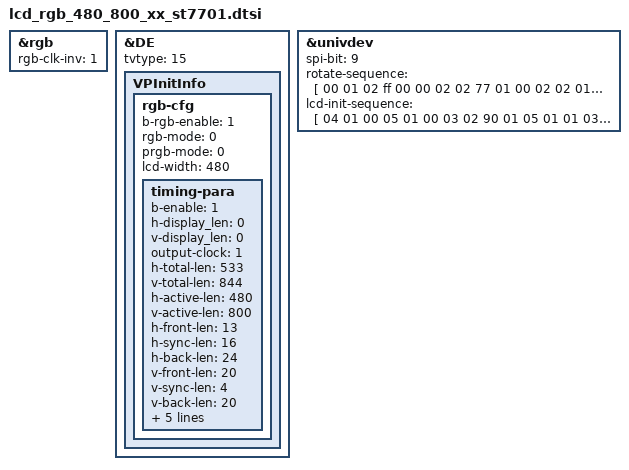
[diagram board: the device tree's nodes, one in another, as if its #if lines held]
&rgb {
	rgb-clk-inv = <1>;
};

&DE {
	tvtype = <15>;
	VPInitInfo {
		rgb-cfg{
			b-rgb-enable = <1>;
			/*
			 * 0: MODE_PRGB
			 * 1: MODE_SRGB
			 */
			rgb-mode = <0>;
			/*
			 * 0: MODE_PRGB_888_10bit
			 * 1: MODE_PRGB_666
			 */
			prgb-mode = <0>;
			lcd-width = <480>;
			timing-para {
				/* bool type, 0 or 1*/
				b-enable = <1>;

				h-display_len = <0>;
				v-display_len = <0>;

				/*
				 * VPO_RGB_CLOCK_27M = 1,
				 * VPO_RGB_CLOCK_33M = 2,
				 * VPO_RGB_CLOCK_49M = 3,
				 * VPO_RGB_CLOCK_66M = 4,
				 * VPO_RGB_CLOCK_74M = 5,
				 * VPO_RGB_CLOCK_85M = 6,
				 * VPO_RGB_CLOCK_108M = 7,
				 * VPO_RGB_CLOCK_6_6M = 8,
				 * VPO_RGB_CLOCK_9M = 9,
				 * VPO_RGB_CLOCK_39_6M = 10,
				 * VPO_RGB_CLOCK_74_25M = 11,
				 * VPO_RGB_CLOCK_148_5M = 12,
				 * VPO_RGB_CLOCK_54M = 13,
				 * VPO_RGB_CLOCK_132M = 14,//H1600
				 * VPO_RGB_CLOCK_297M = 15,//H1600 only De4k
				 * VPO_RGB_CLOCK_DPLL = 0xFF,//H1600
				*/
				output-clock = <1>;

				h-total-len = <533>;
				v-total-len = <844>;

				h-active-len = <480>;
				v-active-len = <800>;

				h-front-len = <13>;
				h-sync-len = <16>;
				h-back-len = <24>;

				v-front-len = <20>;
				v-sync-len = <4>;
				v-back-len = <20>;

				/* bool type, 0 or 1*/
				h-sync-level = <0>;
				/* bool type, 0 or 1*/
				v-sync-level = <0>;

				/* bool type, 0 or 1*/
				active-polarity = <1>;
				frame-rate = <60000>;

				/*
				31	De_dig_pll_en
				25:16	DE_DIG_PLL_M_ctrl
				13:8	DE_DIG_PLL_N_ctrl
				5:0	DE_DIG_PLL_L_ctrl
				de_digpll_clock = 24 *(M+1)/((N+1)*(L+1))
				*/
				dpll-clock-reg-value = <0x0>;
			};
		};
	};
};

#ifdef LCD_UNIVDEV_ENABLED
&univdev{
	spi-bit = <9>;
	rotate-sequence = [
		00 01 02 ff 00
		00 02 02 77 01
		00 02 02 01 01
		00 02 02 00 01
		00 02 02 00 01
		00 02 02 10 01
		00 01 02 c7 00
		00 02 02 00 01
		01 01 02 ff 00
		01 02 02 77 01
		01 02 02 01 01
		01 02 02 00 01
		01 02 02 00 01
		01 02 02 10 01
		01 01 02 c7 00
		01 02 02 04 01
	];
	lcd-init-sequence = [
		04 01 00
		05 01 00
		03 02 90 01
		05 01 01
		03 02 90 01
		01 02 01 00
		03 01 78
		01 02 ff 00
		02 02 77 01
		02 02 01 01
		02 02 00 01
		02 02 00 01
		02 02 11 01
		01 02 d1 00
		02 02 11 01
		01 02 11 00
		03 01 78
		01 02 ff 00
		02 02 77 01
		02 02 01 01
		02 02 00 01
		02 02 00 01
		02 02 10 01
		01 02 c0 00
		02 02 63 01
		02 02 00 01
		01 02 c1 00
		02 02 16 01
		02 02 02 01
		01 02 c2 00
		02 02 01 01
		02 02 08 01
		01 02 cc 00
		02 02 10 01
		01 02 b0 00
		02 02 00 01
		02 02 16 01
		02 02 1e 01
		02 02 0e 01
		02 02 11 01
		02 02 06 01
		02 02 10 01
		02 02 09 01
		02 02 09 01
		02 02 2b 01
		02 02 06 01
		02 02 13 01
		02 02 10 01
		02 02 2a 01
		02 02 31 01
		02 02 1f 01
		01 02 b1 00
		02 02 00 01
		02 02 16 01
		02 02 1e 01
		02 02 0d 01
		02 02 11 01
		02 02 06 01
		02 02 10 01
		02 02 07 01
		02 02 08 01
		02 02 2c 01
		02 02 07 01
		02 02 15 01
		02 02 14 01
		02 02 2b 01
		02 02 30 01
		02 02 1f 01
		01 02 ff 00
		02 02 77 01
		02 02 01 01
		02 02 00 01
		02 02 00 01
		02 02 11 01
		01 02 b0 00
		02 02 3d 01
		01 02 b1 00
		02 02 71 01
		01 02 b2 00
		02 02 87 01
		01 02 b3 00
		02 02 80 01
		01 02 b5 00
		02 02 47 01
		01 02 b7 00
		02 02 85 01
		01 02 b8 00
		02 02 20 01
		01 02 b9 00
		02 02 10 01
		01 02 bc 00
		02 02 3e 01
		01 02 c1 00
		02 02 78 01
		01 02 c2 00
		02 02 78 01
		01 02 d0 00
		02 02 88 01
		03 01 64
		01 02 e0 00
		02 02 00 01
		02 02 00 01
		02 02 02 01
		01 02 e1 00
		02 02 08 01
		02 02 00 01
		02 02 0a 01
		02 02 00 01
		02 02 09 01
		02 02 00 01
		02 02 0b 01
		02 02 00 01
		02 02 00 01
		02 02 44 01
		02 02 44 01
		01 02 e2 00
		02 02 00 01
		02 02 00 01
		02 02 00 01
		02 02 00 01
		02 02 00 01
		02 02 00 01
		02 02 00 01
		02 02 00 01
		02 02 00 01
		02 02 00 01
		02 02 00 01
		02 02 00 01
		02 02 00 01
		01 02 e3 00
		02 02 00 01
		02 02 00 01
		02 02 33 01
		02 02 33 01
		01 02 e4 00
		02 02 22 01
		02 02 22 01
		01 02 e5 00
		02 02 11 01
		02 02 40 01
		02 02 a0 01
		02 02 a0 01
		02 02 0d 01
		02 02 40 01
		02 02 a0 01
		02 02 a0 01
		02 02 13 01
		02 02 40 01
		02 02 a0 01
		02 02 a0 01
		02 02 0f 01
		02 02 40 01
		02 02 a0 01
		02 02 a0 01
		01 02 e6 00
		02 02 00 01
		02 02 00 01
		02 02 33 01
		02 02 33 01
		01 02 e7 00
		02 02 22 01
		02 02 22 01
		01 02 e8 00
		02 02 10 01
		02 02 40 01
		02 02 a0 01
		02 02 a0 01
		02 02 0c 01
		02 02 40 01
		02 02 a0 01
		02 02 a0 01
		02 02 12 01
		02 02 40 01
		02 02 a0 01
		02 02 a0 01
		02 02 0e 01
		02 02 40 01
		02 02 a0 01
		02 02 a0 01
		01 02 eb 00
		02 02 02 01
		02 02 00 01
		02 02 e4 01
		02 02 e4 01
		02 02 11 01
		02 02 00 01
		02 02 00 01
		01 02 ec 00
		02 02 00 01
		02 02 00 01
		01 02 ed 00
		02 02 ab 01
		02 02 ff 01
		02 02 75 01
		02 02 64 01
		02 02 01 01
		02 02 ff 01
		02 02 ff 01
		02 02 ff 01
		02 02 ff 01
		02 02 ff 01
		02 02 ff 01
		02 02 10 01
		02 02 46 01
		02 02 57 01
		02 02 ff 01
		02 02 ba 01
		01 02 ff 00
		02 02 77 01
		02 02 01 01
		02 02 00 01
		02 02 00 01
		02 02 00 01
		01 02 36 00
		02 02 10 01
		01 02 29 00
		03 01 14
	];
};
#endif
